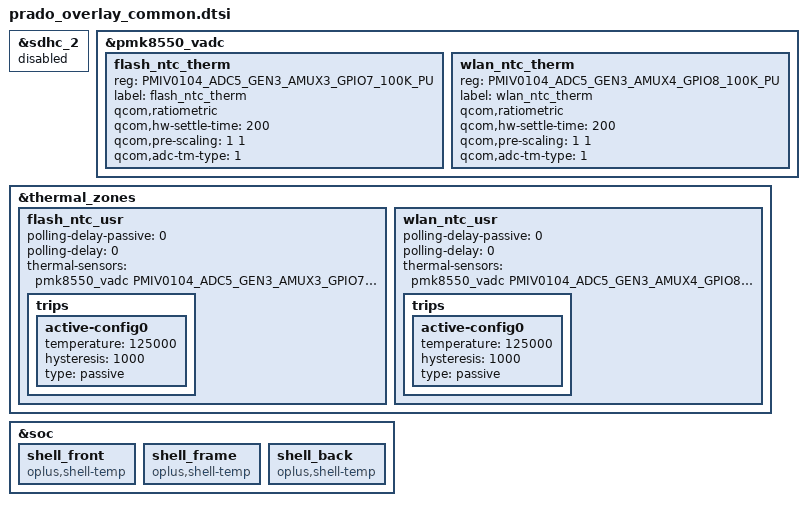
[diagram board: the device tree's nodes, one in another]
#include <dt-bindings/iio/qcom,spmi-adc5-gen3-pmiv0104.h>

//#ifdef OPLUS_FEATURE_STORAGE
&sdhc_2 {
	status = "disabled";
};
//#endif /* OPLUS_FEATURE_STORAGE */

&pmk8550_vadc {
	flash_ntc_therm {
		reg = <PMIV0104_ADC5_GEN3_AMUX3_GPIO7_100K_PU>;
		label = "flash_ntc_therm";
		qcom,ratiometric;
		qcom,hw-settle-time = <200>;
		qcom,pre-scaling = <1 1>;
		qcom,adc-tm-type = <1>;
	};
	wlan_ntc_therm {
		reg = <PMIV0104_ADC5_GEN3_AMUX4_GPIO8_100K_PU>;
		label = "wlan_ntc_therm";
		qcom,ratiometric;
		qcom,hw-settle-time = <200>;
		qcom,pre-scaling = <1 1>;
		qcom,adc-tm-type = <1>;
	};
};
&thermal_zones {
	flash_ntc_usr {
		polling-delay-passive = <0>;
		polling-delay = <0>;
		thermal-sensors = <&pmk8550_vadc PMIV0104_ADC5_GEN3_AMUX3_GPIO7_100K_PU>;
		trips {
			active-config0 {
				temperature = <125000>;
				hysteresis = <1000>;
				type = "passive";
			};
		};
	};
	wlan_ntc_usr {
		polling-delay-passive = <0>;
		polling-delay = <0>;
		thermal-sensors = <&pmk8550_vadc PMIV0104_ADC5_GEN3_AMUX4_GPIO8_100K_PU>;
		trips {
			active-config0 {
				temperature = <125000>;
				hysteresis = <1000>;
				type = "passive";
			};
		};
	};
};
&soc {
	//#ifdef OPLUS_FEATURE_THERMAL_HORAE
	shell_front {
		compatible = "oplus,shell-temp";
	};

	shell_frame {
		compatible = "oplus,shell-temp";
	};

	shell_back {
		compatible = "oplus,shell-temp";
	};
	//#endif /* OPLUS_FEATURE_THERMAL_HORAE */
};
